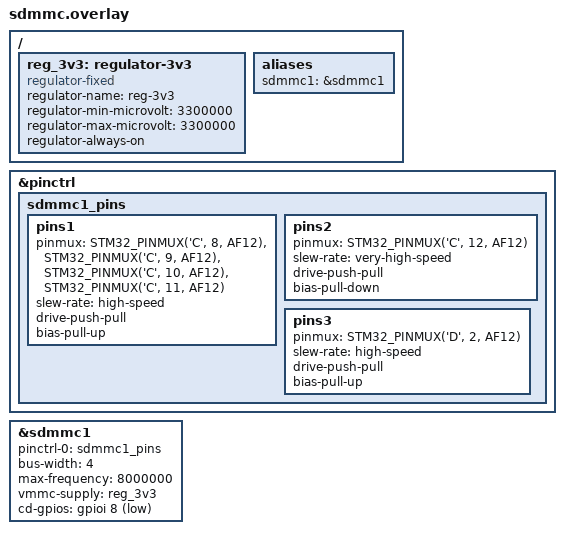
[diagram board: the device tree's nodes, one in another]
/*
 * SD card overlay for Manikin Communication Node
 *
 * Configure SDMMC1 with SD card connected to J1 connector pins:
 * PC8  - SDMMC1_D0  - J1-59
 * PC9  - SDMMC1_D1  - J1-61
 * PC10 - SDMMC1_D2  - J1-63
 * PC11 - SDMMC1_D3  - J1-65
 * PC12 - SDMMC1_CK  - J1-55
 * PD2  - SDMMC1_CMD - J1-57
 */

/ {
    /* Define a 3.3V regulator for SD card power supply */
    reg_3v3: regulator-3v3 {
        compatible = "regulator-fixed";
        regulator-name = "reg-3v3";
        regulator-min-microvolt = <3300000>;
        regulator-max-microvolt = <3300000>;
        regulator-always-on;
    };

    aliases {
        sdmmc1 = &sdmmc1;
    };
};

&pinctrl {
    /* Define SDMMC1 pins for J1 connector with correct pull resistors */
    sdmmc1_pins: sdmmc1_pins {
        /* Data pins D0-D3 */
        pins1 {
            pinmux = <STM32_PINMUX('C', 8, AF12)>,  /* SDMMC1_D0 - J1-59 */
                     <STM32_PINMUX('C', 9, AF12)>,  /* SDMMC1_D1 - J1-61 */
                     <STM32_PINMUX('C', 10, AF12)>, /* SDMMC1_D2 - J1-63 */
                     <STM32_PINMUX('C', 11, AF12)>; /* SDMMC1_D3 - J1-65 */
            slew-rate = "high-speed";
            drive-push-pull;
            bias-pull-up;
        };
        
        /* Clock pin needs pull-down, CMD needs pull-up */
        pins2 {
            pinmux = <STM32_PINMUX('C', 12, AF12)>; /* SDMMC1_CK - J1-55 */
            slew-rate = "very-high-speed";
            drive-push-pull;
            bias-pull-down;
        };
        
        pins3 {
            pinmux = <STM32_PINMUX('D', 2, AF12)>;  /* SDMMC1_CMD - J1-57 */
            slew-rate = "high-speed";
            drive-push-pull;
            bias-pull-up;
        };
    };
};

&sdmmc1 {
    status = "okay";
    pinctrl-0 = <&sdmmc1_pins>;
    pinctrl-names = "default";
    bus-width = <4>;
    max-frequency = <8000000>; /* Lower clock speed for better reliability */
    vmmc-supply = <&reg_3v3>;
    
    /* Simple configuration focused on reliability */
    cd-gpios = <&gpioi 8 (GPIO_ACTIVE_LOW | GPIO_PULL_UP)>;
}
